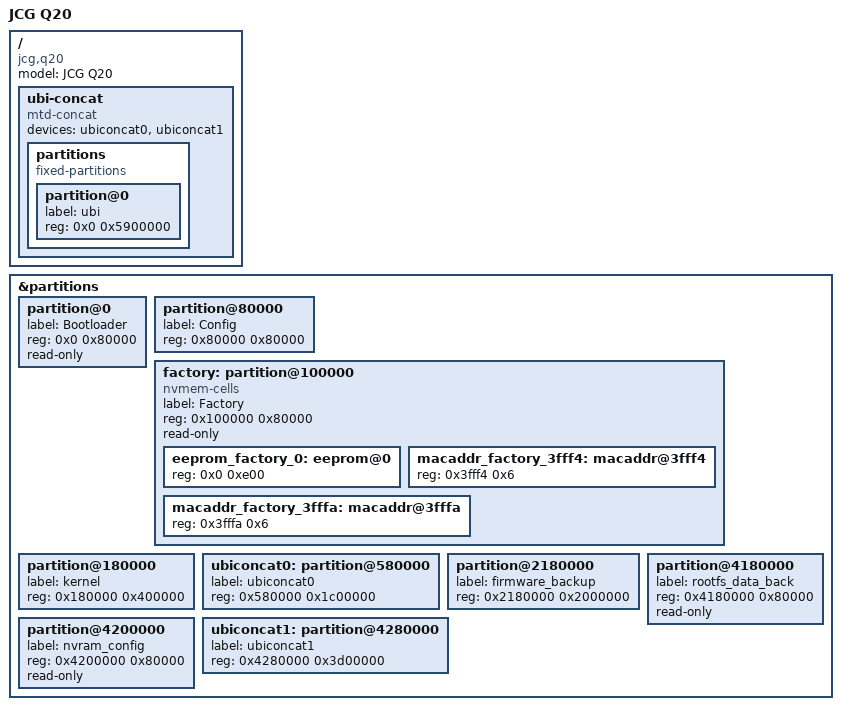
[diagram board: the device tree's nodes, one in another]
// SPDX-License-Identifier: GPL-2.0-or-later OR MIT

#include "mt7621_jcg_q20.dtsi"

/ {
	compatible = "jcg,q20", "mediatek,mt7621-soc";
	model = "JCG Q20";

	ubi-concat {
		compatible = "mtd-concat";
		devices = <&ubiconcat0 &ubiconcat1>;

		partitions {
			compatible = "fixed-partitions";
			#address-cells = <1>;
			#size-cells = <1>;

			partition@0 {
				label = "ubi";
				reg = <0x0 0x5900000>;
			};
		};
	};
};

&partitions {
	partition@0 {
		label = "Bootloader";
		reg = <0x0 0x80000>;
		read-only;
	};

	partition@80000 {
		label = "Config";
		reg = <0x80000 0x80000>;
	};

	factory: partition@100000 {
		label = "Factory";
		reg = <0x100000 0x80000>;
		read-only;

		compatible = "nvmem-cells";
		#address-cells = <1>;
		#size-cells = <1>;

		eeprom_factory_0: eeprom@0 {
			reg = <0x0 0xe00>;
		};

		macaddr_factory_3fff4: macaddr@3fff4 {
			reg = <0x3fff4 0x6>;
		};

		macaddr_factory_3fffa: macaddr@3fffa {
			reg = <0x3fffa 0x6>;
		};
	};

	partition@180000 {
		label = "kernel";
		reg = <0x180000 0x400000>;
	};

	ubiconcat0: partition@580000 {
		label = "ubiconcat0";
		reg = <0x580000 0x1c00000>;
	};

	partition@2180000 {
		label = "firmware_backup";
		reg = <0x2180000 0x2000000>;
	};

	partition@4180000 {
		label = "rootfs_data_back";
		reg = <0x4180000 0x80000>;
		read-only;
	};

	partition@4200000 {
		label = "nvram_config";
		reg = <0x4200000 0x80000>;
		read-only;
	};

	ubiconcat1: partition@4280000 {
		label = "ubiconcat1";
		reg = <0x4280000 0x3d00000>;
	};

	/*
	 * last 512 KiB are for the bad block table
	 */
};
